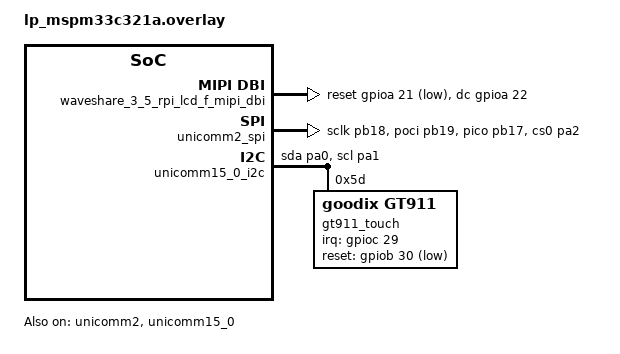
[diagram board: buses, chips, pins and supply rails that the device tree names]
/*
 * Copyright (c) 2026 Texas Instruments
 *
 * SPDX-License-Identifier: Apache-2.0
 */

#include <zephyr/dt-bindings/i2c/i2c.h>

&waveshare_3_5_rpi_lcd_f_mipi_dbi {
	dc-gpios    = <&gpioa 22 GPIO_ACTIVE_HIGH>;
	reset-gpios = <&gpioa 21 GPIO_ACTIVE_LOW>;
	spi-dev     = <&unicomm2_spi>;
};

/ {
	display_backlight: display-backlight {
		status = "disabled";
		compatible = "regulator-fixed";
		regulator-name = "display-backlight";
		enable-gpios = <&gpioa 16 GPIO_ACTIVE_HIGH>;
		regulator-boot-on;
	};
};

&unicomm2 {
	status = "okay";
};

&unicomm15_0 {
	status = "okay";
};

&unicomm2_spi {
	status = "okay";
	pinctrl-0 = <&uc2_sclk_pb18 &uc2_poci_pb19 &uc2_pico_pb17 &uc2_cs0_pa2>;
	pinctrl-names = "default";
};

/*
 * GT911 on native I2C0 (PA0=SDA / PA1=SCL). This bus has the board's populated
 * 2.2k pull-ups (jumpers J16/J17). PB2/PB3 (i2c1) has no pull-ups and PB3 is
 * tied to the S2 button by J23, so i2c0 is used instead. i2c0 driver support
 * comes from the cherry-picked PR #117311.
 */
&unicomm15_0_i2c {
	status = "okay";
	pinctrl-0 = <&uc15_0_sda_pa0 &uc15_0_scl_pa1>;
	pinctrl-names = "default";

	gt911_touch: gt911@5d {
		compatible = "goodix,gt911";
		reg = <0x5d>;
		alt-addr = <0x14>;
		irq-gpios   = <&gpioc 29 GPIO_ACTIVE_HIGH>;
		reset-gpios = <&gpiob 30 GPIO_ACTIVE_LOW>;
		screen-width  = <320>;
		screen-height = <480>;
		status = "okay";
	};
};
